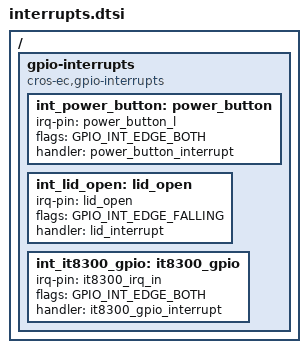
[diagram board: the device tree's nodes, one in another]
/* Copyright 2025 The ChromiumOS Authors
 * Use of this source code is governed by a BSD-style license that can be
 * found in the LICENSE file.
 */

/ {
	gpio-interrupts {
		compatible = "cros-ec,gpio-interrupts";

		int_power_button: power_button {
			irq-pin = <&power_button_l>;
			flags = <GPIO_INT_EDGE_BOTH>;
			handler = "power_button_interrupt";
		};
		int_lid_open: lid_open {
			irq-pin = <&lid_open>;
			flags = <GPIO_INT_EDGE_FALLING>;
			handler = "lid_interrupt";
		};
		int_it8300_gpio: it8300_gpio {
			irq-pin = <&it8300_irq_in>;
			flags = <GPIO_INT_EDGE_BOTH>;
			handler = "it8300_gpio_interrupt";
		};

	};
};
